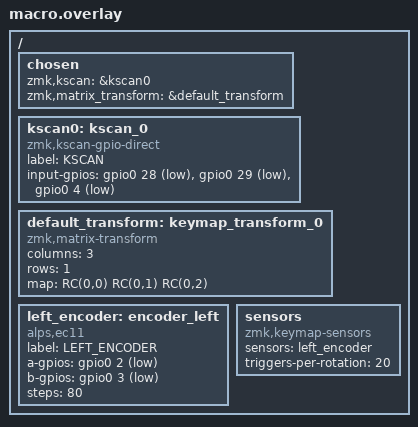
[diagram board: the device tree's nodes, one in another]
#include <dt-bindings/zmk/matrix_transform.h>
#include <dt-bindings/gpio/gpio.h> /* 이 줄이 없으면 GPIO_ACTIVE_LOW를 못 읽고 에러가 납니다! */

/ {
    chosen {
        zmk,kscan = &kscan0;
        zmk,matrix_transform = &default_transform;
    };

    kscan0: kscan_0 {
        compatible = "zmk,kscan-gpio-direct";
        label = "KSCAN";
        /* XIAO BLE의 D2, D3, D4 물리 핀 번호 적용 */
        input-gpios
            = <&gpio0 28 (GPIO_ACTIVE_LOW | GPIO_PULL_UP)> // D2 핀
            , <&gpio0 29 (GPIO_ACTIVE_LOW | GPIO_PULL_UP)> // D3 핀
            , <&gpio0 4  (GPIO_ACTIVE_LOW | GPIO_PULL_UP)> // D4 핀
            ;
    };

    default_transform: keymap_transform_0 {
        compatible = "zmk,matrix-transform";
        columns = <3>;
        rows = <1>;
        map = <
            RC(0,0) RC(0,1) RC(0,2)
        >;
    };

    left_encoder: encoder_left {
        compatible = "alps,ec11";
        label = "LEFT_ENCODER";
        /* XIAO BLE의 D0, D1 물리 핀 번호 적용 */
        a-gpios = <&gpio0 2 (GPIO_ACTIVE_LOW | GPIO_PULL_UP)>; // D0 핀
        b-gpios = <&gpio0 3 (GPIO_ACTIVE_LOW | GPIO_PULL_UP)>; // D1 핀
        steps = <80>;
        status = "okay";
    };

    sensors: sensors {
        compatible = "zmk,keymap-sensors";
        sensors = <&left_encoder>;
        triggers-per-rotation = <20>;
    };
};
